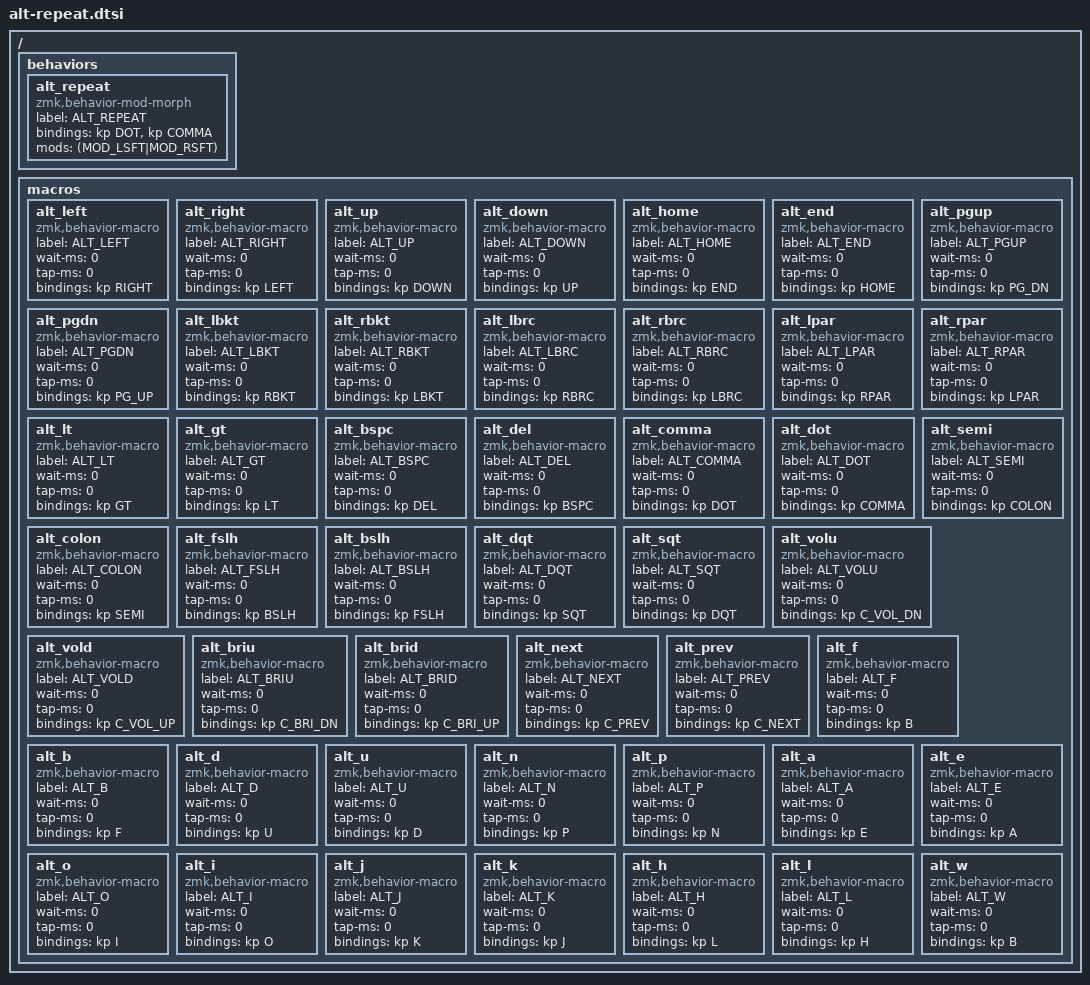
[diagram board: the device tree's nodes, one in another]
/*
 * Alternate Repeat - Similar to QMK's QK_AREP
 *
 * This implementation provides alternate repeat functionality inspired by QMK.
 * It includes default alternate key pairs for navigation, brackets, media keys,
 * and common programming shortcuts.
 *
 * Default Alternate Pairs (from QMK):
 * Navigation:
 * - Left ↔ Right Arrow
 * - Up ↔ Down Arrow
 * - Home ↔ End
 * - Page Up ↔ Page Down
 *
 * Brackets:
 * - [ ↔ ]
 * - { ↔ }
 * - ( ↔ )
 * - < ↔ >
 *
 * Misc:
 * - Backspace ↔ Delete
 * - , ↔ .
 * - ; ↔ :
 * - / ↔ \
 *
 * Media:
 * - Volume Up ↔ Volume Down
 * - Brightness Up ↔ Brightness Down
 * - Next Track ↔ Previous Track
 *
 * Programming:
 * - Forward ↔ Backward
 * - Next ↔ Previous
 *
 * Note: Due to ZMK's devicetree-based architecture, this implementation uses
 * a combination of behaviors and macros. For full context-aware alternates
 * like QMK's get_alt_repeat_key_keycode_user(), custom C code would be needed.
 */

/ {
    behaviors {
        /*
         * Main alternate repeat behavior
         * This is a basic implementation that handles common punctuation pairs.
         * For directional keys and more complex alternates, use dedicated macros.
         */
        alt_repeat: alt_repeat {
            compatible = "zmk,behavior-mod-morph";
            label = "ALT_REPEAT";
            #binding-cells = <0>;
            bindings = <&kp DOT>, <&kp COMMA>;  // Default: . ↔ ,
            mods = <(MOD_LSFT|MOD_RSFT)>;
        };
    };

    macros {
        /*
         * Navigation Alternates
         */

        // Left ↔ Right Arrow
        alt_left: alt_left {
            compatible = "zmk,behavior-macro";
            label = "ALT_LEFT";
            #binding-cells = <0>;
            wait-ms = <0>;
            tap-ms = <0>;
            bindings = <&kp RIGHT>;
        };

        alt_right: alt_right {
            compatible = "zmk,behavior-macro";
            label = "ALT_RIGHT";
            #binding-cells = <0>;
            wait-ms = <0>;
            tap-ms = <0>;
            bindings = <&kp LEFT>;
        };

        // Up ↔ Down Arrow
        alt_up: alt_up {
            compatible = "zmk,behavior-macro";
            label = "ALT_UP";
            #binding-cells = <0>;
            wait-ms = <0>;
            tap-ms = <0>;
            bindings = <&kp DOWN>;
        };

        alt_down: alt_down {
            compatible = "zmk,behavior-macro";
            label = "ALT_DOWN";
            #binding-cells = <0>;
            wait-ms = <0>;
            tap-ms = <0>;
            bindings = <&kp UP>;
        };

        // Home ↔ End
        alt_home: alt_home {
            compatible = "zmk,behavior-macro";
            label = "ALT_HOME";
            #binding-cells = <0>;
            wait-ms = <0>;
            tap-ms = <0>;
            bindings = <&kp END>;
        };

        alt_end: alt_end {
            compatible = "zmk,behavior-macro";
            label = "ALT_END";
            #binding-cells = <0>;
            wait-ms = <0>;
            tap-ms = <0>;
            bindings = <&kp HOME>;
        };

        // Page Up ↔ Page Down
        alt_pgup: alt_pgup {
            compatible = "zmk,behavior-macro";
            label = "ALT_PGUP";
            #binding-cells = <0>;
            wait-ms = <0>;
            tap-ms = <0>;
            bindings = <&kp PG_DN>;
        };

        alt_pgdn: alt_pgdn {
            compatible = "zmk,behavior-macro";
            label = "ALT_PGDN";
            #binding-cells = <0>;
            wait-ms = <0>;
            tap-ms = <0>;
            bindings = <&kp PG_UP>;
        };

        /*
         * Bracket Alternates
         */

        // [ ↔ ]
        alt_lbkt: alt_lbkt {
            compatible = "zmk,behavior-macro";
            label = "ALT_LBKT";
            #binding-cells = <0>;
            wait-ms = <0>;
            tap-ms = <0>;
            bindings = <&kp RBKT>;
        };

        alt_rbkt: alt_rbkt {
            compatible = "zmk,behavior-macro";
            label = "ALT_RBKT";
            #binding-cells = <0>;
            wait-ms = <0>;
            tap-ms = <0>;
            bindings = <&kp LBKT>;
        };

        // { ↔ }
        alt_lbrc: alt_lbrc {
            compatible = "zmk,behavior-macro";
            label = "ALT_LBRC";
            #binding-cells = <0>;
            wait-ms = <0>;
            tap-ms = <0>;
            bindings = <&kp RBRC>;
        };

        alt_rbrc: alt_rbrc {
            compatible = "zmk,behavior-macro";
            label = "ALT_RBRC";
            #binding-cells = <0>;
            wait-ms = <0>;
            tap-ms = <0>;
            bindings = <&kp LBRC>;
        };

        // ( ↔ )
        alt_lpar: alt_lpar {
            compatible = "zmk,behavior-macro";
            label = "ALT_LPAR";
            #binding-cells = <0>;
            wait-ms = <0>;
            tap-ms = <0>;
            bindings = <&kp RPAR>;
        };

        alt_rpar: alt_rpar {
            compatible = "zmk,behavior-macro";
            label = "ALT_RPAR";
            #binding-cells = <0>;
            wait-ms = <0>;
            tap-ms = <0>;
            bindings = <&kp LPAR>;
        };

        // < ↔ >
        alt_lt: alt_lt {
            compatible = "zmk,behavior-macro";
            label = "ALT_LT";
            #binding-cells = <0>;
            wait-ms = <0>;
            tap-ms = <0>;
            bindings = <&kp GT>;
        };

        alt_gt: alt_gt {
            compatible = "zmk,behavior-macro";
            label = "ALT_GT";
            #binding-cells = <0>;
            wait-ms = <0>;
            tap-ms = <0>;
            bindings = <&kp LT>;
        };

        /*
         * Misc Alternates
         */

        // Backspace ↔ Delete
        alt_bspc: alt_bspc {
            compatible = "zmk,behavior-macro";
            label = "ALT_BSPC";
            #binding-cells = <0>;
            wait-ms = <0>;
            tap-ms = <0>;
            bindings = <&kp DEL>;
        };

        alt_del: alt_del {
            compatible = "zmk,behavior-macro";
            label = "ALT_DEL";
            #binding-cells = <0>;
            wait-ms = <0>;
            tap-ms = <0>;
            bindings = <&kp BSPC>;
        };

        // , ↔ .
        alt_comma: alt_comma {
            compatible = "zmk,behavior-macro";
            label = "ALT_COMMA";
            #binding-cells = <0>;
            wait-ms = <0>;
            tap-ms = <0>;
            bindings = <&kp DOT>;
        };

        alt_dot: alt_dot {
            compatible = "zmk,behavior-macro";
            label = "ALT_DOT";
            #binding-cells = <0>;
            wait-ms = <0>;
            tap-ms = <0>;
            bindings = <&kp COMMA>;
        };

        // ; ↔ :
        alt_semi: alt_semi {
            compatible = "zmk,behavior-macro";
            label = "ALT_SEMI";
            #binding-cells = <0>;
            wait-ms = <0>;
            tap-ms = <0>;
            bindings = <&kp COLON>;
        };

        alt_colon: alt_colon {
            compatible = "zmk,behavior-macro";
            label = "ALT_COLON";
            #binding-cells = <0>;
            wait-ms = <0>;
            tap-ms = <0>;
            bindings = <&kp SEMI>;
        };

        // / ↔ \
        alt_fslh: alt_fslh {
            compatible = "zmk,behavior-macro";
            label = "ALT_FSLH";
            #binding-cells = <0>;
            wait-ms = <0>;
            tap-ms = <0>;
            bindings = <&kp BSLH>;
        };

        alt_bslh: alt_bslh {
            compatible = "zmk,behavior-macro";
            label = "ALT_BSLH";
            #binding-cells = <0>;
            wait-ms = <0>;
            tap-ms = <0>;
            bindings = <&kp FSLH>;
        };

        // " ↔ '
        alt_dqt: alt_dqt {
            compatible = "zmk,behavior-macro";
            label = "ALT_DQT";
            #binding-cells = <0>;
            wait-ms = <0>;
            tap-ms = <0>;
            bindings = <&kp SQT>;
        };

        alt_sqt: alt_sqt {
            compatible = "zmk,behavior-macro";
            label = "ALT_SQT";
            #binding-cells = <0>;
            wait-ms = <0>;
            tap-ms = <0>;
            bindings = <&kp DQT>;
        };

        /*
         * Media Key Alternates
         */

        // Volume Up ↔ Volume Down
        alt_volu: alt_volu {
            compatible = "zmk,behavior-macro";
            label = "ALT_VOLU";
            #binding-cells = <0>;
            wait-ms = <0>;
            tap-ms = <0>;
            bindings = <&kp C_VOL_DN>;
        };

        alt_vold: alt_vold {
            compatible = "zmk,behavior-macro";
            label = "ALT_VOLD";
            #binding-cells = <0>;
            wait-ms = <0>;
            tap-ms = <0>;
            bindings = <&kp C_VOL_UP>;
        };

        // Brightness Up ↔ Brightness Down
        alt_briu: alt_briu {
            compatible = "zmk,behavior-macro";
            label = "ALT_BRIU";
            #binding-cells = <0>;
            wait-ms = <0>;
            tap-ms = <0>;
            bindings = <&kp C_BRI_DN>;
        };

        alt_brid: alt_brid {
            compatible = "zmk,behavior-macro";
            label = "ALT_BRID";
            #binding-cells = <0>;
            wait-ms = <0>;
            tap-ms = <0>;
            bindings = <&kp C_BRI_UP>;
        };

        // Next Track ↔ Previous Track
        alt_next: alt_next {
            compatible = "zmk,behavior-macro";
            label = "ALT_NEXT";
            #binding-cells = <0>;
            wait-ms = <0>;
            tap-ms = <0>;
            bindings = <&kp C_PREV>;
        };

        alt_prev: alt_prev {
            compatible = "zmk,behavior-macro";
            label = "ALT_PREV";
            #binding-cells = <0>;
            wait-ms = <0>;
            tap-ms = <0>;
            bindings = <&kp C_NEXT>;
        };

        /*
         * Programming Shortcuts
         * Note: In QMK these work with modifiers (e.g., Ctrl+F ↔ Ctrl+B)
         * In ZMK, you would bind these with modifiers in your keymap
         */

        // Forward ↔ Backward (F ↔ B)
        alt_f: alt_f {
            compatible = "zmk,behavior-macro";
            label = "ALT_F";
            #binding-cells = <0>;
            wait-ms = <0>;
            tap-ms = <0>;
            bindings = <&kp B>;
        };

        alt_b: alt_b {
            compatible = "zmk,behavior-macro";
            label = "ALT_B";
            #binding-cells = <0>;
            wait-ms = <0>;
            tap-ms = <0>;
            bindings = <&kp F>;
        };

        // Down ↔ Up (D ↔ U)
        alt_d: alt_d {
            compatible = "zmk,behavior-macro";
            label = "ALT_D";
            #binding-cells = <0>;
            wait-ms = <0>;
            tap-ms = <0>;
            bindings = <&kp U>;
        };

        alt_u: alt_u {
            compatible = "zmk,behavior-macro";
            label = "ALT_U";
            #binding-cells = <0>;
            wait-ms = <0>;
            tap-ms = <0>;
            bindings = <&kp D>;
        };

        // Next ↔ Previous (N ↔ P)
        alt_n: alt_n {
            compatible = "zmk,behavior-macro";
            label = "ALT_N";
            #binding-cells = <0>;
            wait-ms = <0>;
            tap-ms = <0>;
            bindings = <&kp P>;
        };

        alt_p: alt_p {
            compatible = "zmk,behavior-macro";
            label = "ALT_P";
            #binding-cells = <0>;
            wait-ms = <0>;
            tap-ms = <0>;
            bindings = <&kp N>;
        };

        // Home ↔ End (A ↔ E)
        alt_a: alt_a {
            compatible = "zmk,behavior-macro";
            label = "ALT_A";
            #binding-cells = <0>;
            wait-ms = <0>;
            tap-ms = <0>;
            bindings = <&kp E>;
        };

        alt_e: alt_e {
            compatible = "zmk,behavior-macro";
            label = "ALT_E";
            #binding-cells = <0>;
            wait-ms = <0>;
            tap-ms = <0>;
            bindings = <&kp A>;
        };

        // Vim jump list: Older ↔ Newer (O ↔ I)
        alt_o: alt_o {
            compatible = "zmk,behavior-macro";
            label = "ALT_O";
            #binding-cells = <0>;
            wait-ms = <0>;
            tap-ms = <0>;
            bindings = <&kp I>;
        };

        alt_i: alt_i {
            compatible = "zmk,behavior-macro";
            label = "ALT_I";
            #binding-cells = <0>;
            wait-ms = <0>;
            tap-ms = <0>;
            bindings = <&kp O>;
        };

        // Vim: Down ↔ Up (J ↔ K)
        alt_j: alt_j {
            compatible = "zmk,behavior-macro";
            label = "ALT_J";
            #binding-cells = <0>;
            wait-ms = <0>;
            tap-ms = <0>;
            bindings = <&kp K>;
        };

        alt_k: alt_k {
            compatible = "zmk,behavior-macro";
            label = "ALT_K";
            #binding-cells = <0>;
            wait-ms = <0>;
            tap-ms = <0>;
            bindings = <&kp J>;
        };

        // Vim: Left ↔ Right (H ↔ L)
        alt_h: alt_h {
            compatible = "zmk,behavior-macro";
            label = "ALT_H";
            #binding-cells = <0>;
            wait-ms = <0>;
            tap-ms = <0>;
            bindings = <&kp L>;
        };

        alt_l: alt_l {
            compatible = "zmk,behavior-macro";
            label = "ALT_L";
            #binding-cells = <0>;
            wait-ms = <0>;
            tap-ms = <0>;
            bindings = <&kp H>;
        };

        // Vim: Forward ↔ Backward by word (W ↔ B)
        alt_w: alt_w {
            compatible = "zmk,behavior-macro";
            label = "ALT_W";
            #binding-cells = <0>;
            wait-ms = <0>;
            tap-ms = <0>;
            bindings = <&kp B>;
        };

        // Note: alt_b is already defined above for F ↔ B pair
        // For W ↔ B, you can use alt_w for W→B and alt_b for B→W
    };
};
